# NUC505_v1 register map
File version: 1.0
Registers are 32-bit, read-write, reset 0x0 unless marked. A register's access mark holds for its fields unless they carry their own. Offsets are from the block's base; [hi:lo] are bit positions; {n}, {i} and the like mark numbered series.

## CLK — CLKCTRL Register Map
Base 0x40000200
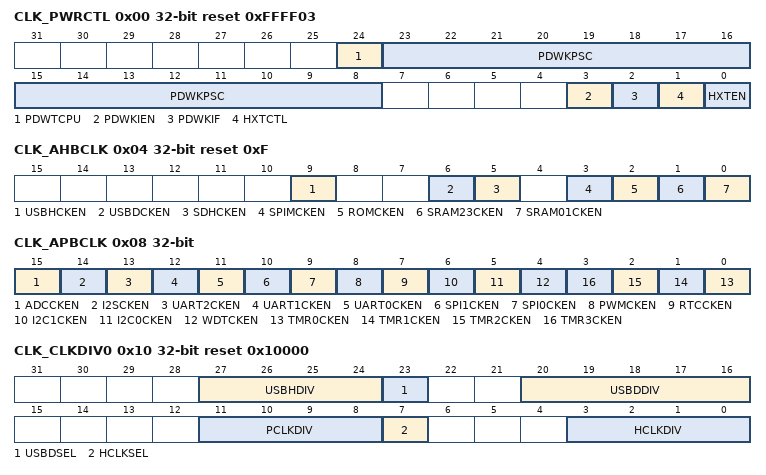
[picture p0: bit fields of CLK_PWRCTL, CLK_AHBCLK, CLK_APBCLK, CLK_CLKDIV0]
0x00 CLK_PWRCTL reset 0xFFFF03 — System Power-down Control Register
  [24] PDWTCPU — Control Power-down Entry Condition
    0=Chip enters Power-down mode when the HXTEN bit is set to 1; 1=Chip enters Power-down mode when the both PDWTCPU and HXTEN bits are set to 1 and CPU run WFI instruction
  [23:8] PDWKPSC — PDWKPSC Counter. Assuming the HXT is stable after the PDWKPSC x 256 HXT cycles, Clock controller would not output clock to system before the counter reaches (PDWKPSC x 256).
  [3] PDWKIEN — Power-down Mode Wake-up Interrupt Enable Control. Note: The interrupt will occur when both PDWKIF and PDWKIEN are set
    0=Power-down Mode Wake-up Interrupt Disabled; 1=Power-down Mode Wake-up Interrupt Enabled
  [2] PDWKIF — Power-down Mode Wake-up Interrupt Flag. Set by "power down wake-up event" indicates that resume from Power-down mode" The flag is set if the GPIO, USBH, USBD, UART, TIMER, WDT, RTC or I2C wake-up occurred. Note1: Write 1 to clear the bit to zero. Note2: This bit works only if PDWKIEN (CLK_PWRCTL[24]) set to 1
  [1] HXTCTL — Power-down Mode Wake-up Pre-divider Counter Enable Control. The HXT pre-divider controls wake-up time from Power-down mode. The chip will delay (PDWKPSC*256) cycles to wait until the HXT is stable after the reset signal.
    0=PDWKPSC counter Disabled; 1=PDWKPSC counter Enabled
  [0] HXTEN — Crystal (Power Down) Control
    0=Crystal off (Power down); 1=Crystal on (Normal operation)
0x04 CLK_AHBCLK reset 0xF — AHB Devices Clock Enable Control Register
  [9] USBHCKEN — USB Host Clock Enable Control
    0=USB Host Clock Disabled; 1=USB Host Clock Enabled
  [6] USBDCKEN — USB Device Clock Enable Control
    0=USB Device Clock Disabled; 1=USB Device Clock Enabled
  [5] SDHCKEN — SDH Clock Enable Control
    0=SDH Clock Disabled; 1=SDH Clock Enabled
  [3] SPIMCKEN — SPIM Clock Enable Control
    0=SPIM Clock Disabled; 1=SPIM Clock Enabled
  [2] ROMCKEN — ROM Clock Enable Control
    0=ROM Clock Disabled; 1=ROM Clock Enabled
  [1] SRAM23CKEN — SRAM#2 Clock Enable Control
    0=SRAM#2 Clock Disabled; 1=SRAM#2 Clock Enabled
  [0] SRAM01CKEN — SRAM#1 Clock Enable Control
    0=SRAM#1 Clock Disabled; 1=SRAM#1 Clock Enabled
0x08 CLK_APBCLK — APB Devices Clock Enable Control Register
  [15] ADCCKEN — ADC Clock Enable Control
    0=ADC Clock Disabled; 1=ADC Clock Enabled
  [14] I2SCKEN — I2S Clock Enable Control
    0=I2S Clock Disabled; 1=I2S Clock Enabled
  [13] UART2CKEN — UART2 Clock Enable Control
    0=UART2 Clock Disabled; 1=UART2 Clock Enabled
  [12] UART1CKEN — UART1 Clock Enable Control
    0=UART1 Clock Disabled; 1=UART1 Clock Enabled
  [11] UART0CKEN — UART0 Clock Enable Control
    0=UART0 Clock Disabled; 1=UART0 Clock Enabled
  [10] SPI1CKEN — SPI1 Clock Enable Control
    0=SPI1 Clock Disabled; 1=SPI1 Clock Enabled
  [9] SPI0CKEN — SPI0 Clock Enable Control
    0=SPI0 Clock Disabled; 1=SPI0 Clock Enabled
  [8] PWMCKEN — PWM Clock Enable Control
    0=PWM Clock Disabled; 1=PWM Clock Enabled
  [7] RTCCKEN — RTC Clock Enable Control
    0=RTC Clock Disabled; 1=RTC Clock Enabled
  [6] I2C1CKEN — I2C1 Clock Enable Control
    0=I2C1 Clock Disabled; 1=I2C1 Clock Enabled
  [5] I2C0CKEN — I2C0 Clock Enable Control
    0=I2C0 Clock Disabled; 1=I2C0 Clock Enabled
  [4] WDTCKEN — Watchdog Timer Clock Enable Control
    0=Watchdog Timer Clock Disabled; 1=Watchdog Timer Clock Enabled
  [n] TMR{n}CKEN (n=0..3) — TIMER{n} Clock Enable Control
    0=TIMER{n} Clock Disabled; 1=TIMER{n} Clock Enabled
0x10 CLK_CLKDIV0 reset 0x10000 — Clock Divider Number Control Register 0
  [27:24] USBHDIV — Defines the Clock Divider Number for USB Host. The actual clock divider number is (USBHDIV+1). So,
  [23] USBDSEL — USB Device Source Clock Select (USBD_SrcCLK)
    0=USB Device Clock source from HXT; 1=USB Device Clock source from PLL_FOUT
  [20:16] USBDDIV — Defines the Clock Divider Number for USB Device. The actual clock divider number is (USBDDIV+1). So,
  [11:8] PCLKDIV — Defines the Clock Divider Number for APB_CLK. The actual clock divider number is (PCLKDIV+1). So,
  [7] HCLKSEL — System Source Clock Select (SYS_SrcCLK)
    0=System Clock source from HXT; 1=System Clock source from PLL_FOUT
  [3:0] HCLKDIV — Defines the Clock Divider Number for SYS_CLK. The actual clock divider number is (HCLKDIV+1). So,
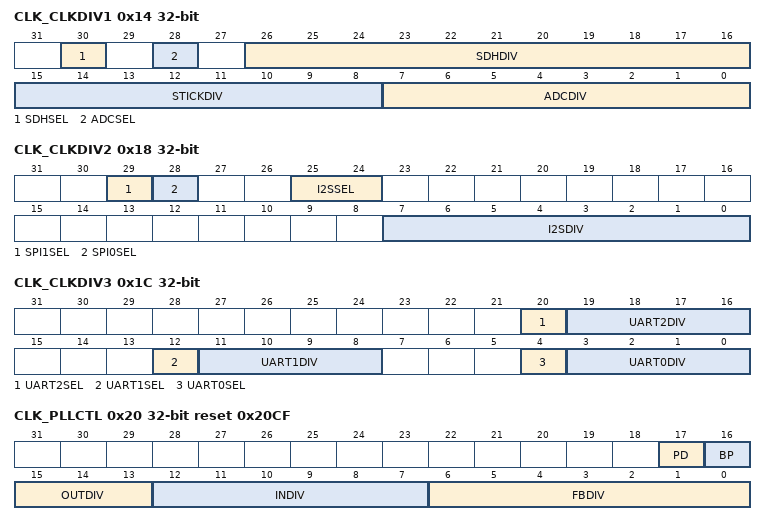
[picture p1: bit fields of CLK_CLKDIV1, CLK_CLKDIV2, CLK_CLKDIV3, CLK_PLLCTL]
0x14 CLK_CLKDIV1 — Clock Divider Number Control Register 1
  [30] SDHSEL — SDH Clock Select (SDH_SrcCLK)
    0=SDH Clock source from HXT; 1=SDH Clock source from PLL_FOUT
  [28] ADCSEL — ADC Clock Select (ADC_SrcCLK)
    0=ADC Clock source from HXT; 1=ADC Clock source from PLL_FOUT
  [26:16] SDHDIV — Defines the Clock Divider Number for SDH. The actual clock divider number is (SDHDIV+1). So,
  [15:8] STICKDIV — Defines the Clock Divider Number for SYS_TICK. The actual clock divider number is (STICKDIV+1). So,
  [7:0] ADCDIV — Defines the Clock Divider Number for ADC. The actual clock divider number is (ADCDIV+1). So,
0x18 CLK_CLKDIV2 — Clock Divider Number Control Register 2
  [29] SPI1SEL — SPI1 Engine Clock Select (SPI1SEL)
    0=SPI1 Engine Clock source from HXT; 1=SPI1 Engine Clock source from PLL_FOUT
  [28] SPI0SEL — SPI0 Engine Clock Select (SPI0SEL)
    0=SPI0 Engine Clock source from HXT; 1=SPI0 Engine Clock source from PLL_FOUT
  [25:24] I2SSEL — I2S Clock Select (I2S_SrcCLK)
    0=I2S Clock source from HXT; 1=I2S Clock source from PLL_FOUT; 3=I2S Clock source from APLL_FOUT
  [7:0] I2SDIV — Defines the Clock Divider Number for I2S. The actual clock divider number is (I2SDIV+1). So,
0x1C CLK_CLKDIV3 — Clock Divider Number Control Register 3
  [20] UART2SEL — UART2 Source Clock Select (UART2_SrcCLK)
    0=UART2 Source Clock source from HXT; 1=UART2 Source Clock source from PLL_FOUT
  [19:16] UART2DIV — Defines the Clock Divider Number for UART2. The actual clock divider number is (UART2DIV +1). So,
  [12] UART1SEL — UART1 Source Clock Select (UART1_SrcCLK)
    0=UART1 Source Clock source from HXT; 1=UART1 Source Clock source from PLL_FOUT
  [11:8] UART1DIV — Defines the Clock Divider Number for UART1. The actual clock divider number is (UART1DIV +1). So,
  [4] UART0SEL — UART0 Source Clock Select (UART0_SrcCLK)
    0=UART0 Source Clock source from HXT; 1=UART0 Source Clock source from PLL_FOUT
  [3:0] UART0DIV — Defines the Clock Divider Number for UART0. The actual clock divider number is (UART0DIV +1). So,
0x20 CLK_PLLCTL reset 0x20CF — PLL Control Register
  [17] PD — Power-down Mode
    0=PLL in Normal mode; 1=PLL in Power-down mode (Default)
  [16] BP — PLL Bypass Control
    0=PLL at Normal mode; 1=Bypass Fin (i.e. Fout = XIN)
  [15:13] OUTDIV — Output Divider Control (P). Set the output divider factor from 1 to 8.
  [12:7] INDIV — Reference Input Divider (M). Set the input reference clock divider factor from 1 to 64.
  [6:0] FBDIV — Feedback Divider Control (N). Set the feedback divider factor from 1 to 128
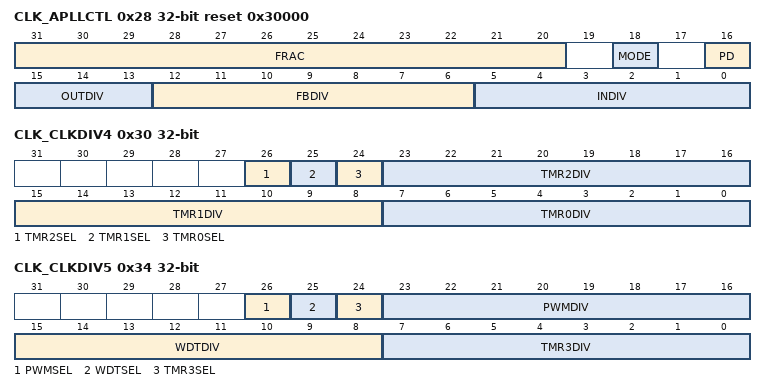
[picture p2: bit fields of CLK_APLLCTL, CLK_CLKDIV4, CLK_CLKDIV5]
0x28 CLK_APLLCTL reset 0x30000 — APLL Control Register
  [31:20] FRAC — Sigma-delta Modulator Control Pins. Set the fractional number of the Feedback divider.
  [18] MODE — Mode Select
    0=Integer mode;; 1=Fraction mode
  [16] PD — Power Down Enable Control
    0=Power down Disabled; 1=Power down Enabled
  [15:13] OUTDIV — Output Divider Control. Set the Output divider factor from 1 to 8.
  [12:6] FBDIV — Feedback Divider Control. Set the Feedback divider factor from 1 to 128.
  [5:0] INDIV — Reference Input Divider Control. Set the reference divider factor from 1 to 64.
0x30 CLK_CLKDIV4 — Clock Divider Number Control Register 4
  [26] TMR2SEL — Timer2 Engine Clock Select (TMR2_SrcCLK)
    0=Timer2 Engine Clock source from RTC_CLK; 1=Timer2 Engine Clock source from HXT
  [25] TMR1SEL — Timer1 Engine Clock Select (TMR1_SrcCLK)
    0=Timer1 Engine Clock source from RTC_CLK; 1=Timer1 Engine Clock source from HXT
  [24] TMR0SEL — Timer0 Engine Clock Select (TMR0_SrcCLK)
    0=Timer0 Engine Clock source from RTC_CLK; 1=Timer0 Engine Clock source from HXT
  [23:16] TMR2DIV — Defines the Clock Divider Number for TMR2. The actual clock divider number is (TMR2DIV+1). So,
  [15:8] TMR1DIV — Defines the Clock Divider Number for TMR1. The actual clock divider number is (TMR1DIV+1). So,
  [7:0] TMR0DIV — Defines the Clock Divider Number for TMR0. The actual clock divider number is (TMR0DIV+1). So,
0x34 CLK_CLKDIV5 — Clock Divider Number Control Register 5
  [26] PWMSEL — PWM Engine Clock Select (PWM_SrcCLK)
    0=PWM Engine Clock source from HXT; 1=PWM Engine Clock source from PLL_FOUT
  [25] WDTSEL — WDT Engine Clock Select (WDT_SrcCLK)
    0=WDT Engine Clock source from RTC_CLK; 1=WDT Engine Clock source from HXT
  [24] TMR3SEL — Timer3 Engine Clock Select (TMR3_SrcCLK)
    0=Timer3 Engine Clock source from RTC_CLK; 1=Timer3 Engine Clock source from HXT
  [23:16] PWMDIV — Define the Clock Divider Number for PWM. The actual clock divider number is (PWMDIV+1). So,
  [15:8] WDTDIV — Define the Clock Divider Number for WDT. The actual clock divider number is (WDTDIV+1). So,
  [7:0] TMR3DIV — Define the Clock Divider Number for TMR3. The actual clock divider number is (TM3DIV+1). So,
